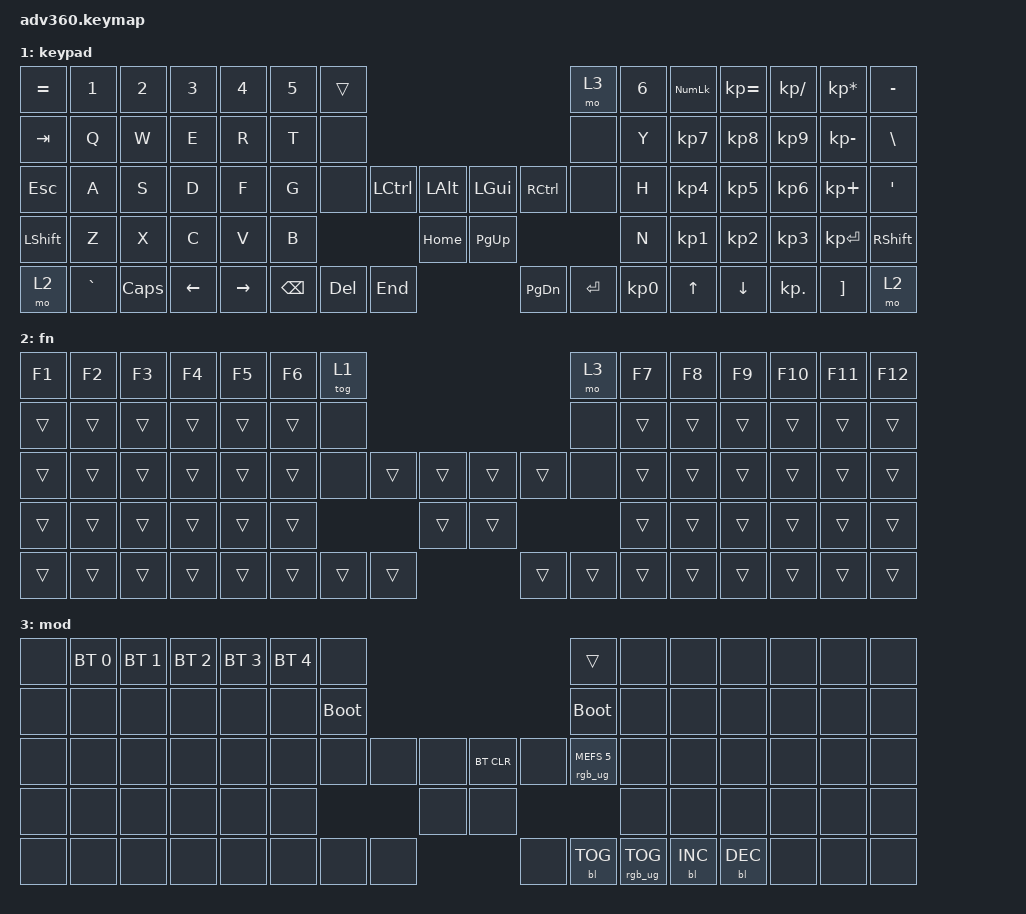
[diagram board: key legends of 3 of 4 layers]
#include <behaviors.dtsi>
#include <dt-bindings/zmk/keys.h>
#include <dt-bindings/zmk/bt.h>
#include <dt-bindings/zmk/rgb.h>
#include <dt-bindings/zmk/backlight.h>
#include "adv360_keypos.h"

#define QUICK_TAP_MS 175
#define XXX &none
#define ___ &trans

#define KEYS_L LN0 LN1 LN2 LN3 LN4 LN5 LT0 LT1 LT2 LT3 LT4 LT5 LM0 LM1 LM2 LM3 LM4 LM5 LB0 LB1 LB2 LB3 LB4 LB5  // left-hand keys
#define KEYS_R RN0 RN1 RN2 RN3 RN4 RN5 RT0 RT1 RT2 RT3 RT4 RT5 RM0 RM1 RM2 RM3 RM4 RM5 RB0 RB1 RB2 RB3 RB4 RB5  // right-hand keys
#define THUMBS LH2 LH1 LH0 RH0 RH1 RH2

#define ZMK_HELPER_STRINGIFY(x) #x
/* ZMK_BEHAVIOR */

#define ZMK_BEHAVIOR_CORE_caps_word       compatible = "zmk,behavior-caps-word";       #binding-cells = <0>
#define ZMK_BEHAVIOR_CORE_dynamic_macro   compatible = "zmk,behavior-dynamic-macro";   #binding-cells = <1>
#define ZMK_BEHAVIOR_CORE_hold_tap        compatible = "zmk,behavior-hold-tap";        #binding-cells = <2>
#define ZMK_BEHAVIOR_CORE_key_repeat      compatible = "zmk,behavior-key-repeat";      #binding-cells = <0>
#define ZMK_BEHAVIOR_CORE_macro           compatible = "zmk,behavior-macro";           #binding-cells = <0>
#define ZMK_BEHAVIOR_CORE_macro_one_param compatible = "zmk,behavior-macro-one-param"; #binding-cells = <1>
#define ZMK_BEHAVIOR_CORE_macro_two_param compatible = "zmk,behavior-macro-two-param"; #binding-cells = <2>
#define ZMK_BEHAVIOR_CORE_mod_morph       compatible = "zmk,behavior-mod-morph";       #binding-cells = <0>
#define ZMK_BEHAVIOR_CORE_sticky_key      compatible = "zmk,behavior-sticky-key";      #binding-cells = <1>
#define ZMK_BEHAVIOR_CORE_tap_dance       compatible = "zmk,behavior-tap-dance";       #binding-cells = <0>
#define ZMK_BEHAVIOR_CORE_tri_state       compatible = "zmk,behavior-tri-state";       #binding-cells = <0>

#define ZMK_BEHAVIOR(name, type, ...) \
    / { \
        behaviors { \
            name: name { \
                label = ZMK_HELPER_STRINGIFY(ZB_ ## name); \
                ZMK_BEHAVIOR_CORE_ ## type; \
                __VA_ARGS__ \
            }; \
        }; \
    };

// removed         //global-quick-tap-ms = <150>;
#define MAKE_HRM(NAME, HOLD, TAP, TRIGGER_POS) \
    ZMK_BEHAVIOR(NAME, hold_tap, \
        flavor = "tap-unless-interrupted"; \
        tapping-term-ms = <200>; \
        quick-tap-ms = <QUICK_TAP_MS>; \
        global-quick-tap; \
        bindings = <HOLD>, <TAP>; \
        hold-trigger-key-positions = <TRIGGER_POS>; \
        hold-trigger-on-release; \
    )
MAKE_HRM(hml, &kp, &kp, KEYS_R THUMBS)  // left-hand HRMs
MAKE_HRM(hmr, &kp, &kp, KEYS_L THUMBS)  // right-hand HRMs

//MAKE_HRM(hml_repeat, &kp, &key_repeat, KEYS_R THUMBS)  // used for HRM-combo
//MAKE_HRM(hmr_lpar_lt, &kp, &lpar_lt, KEYS_L THUMBS)    // "    "   "   "
//MAKE_HRM(hmr_rpar_gt, &kp, &rpar_gt, KEYS_L THUMBS)    // "    "   "   "

//#define AS(keycode) &as LS(keycode) keycode     // Autoshift Macro
#define HYP LC(LA(LGUI))
#define CW &caps_word
//#define _SCRNS &kp LG(LS(NUMBER_4))

/ {
    behaviors {
      #include "macros.dtsi"
    };

  keymap {
    compatible = "zmk,keymap";

    default_layer {
      bindings = <
        &kp EQUAL &kp N1    &kp N2   &kp N3   &kp N4     &kp N5 &tog 1                                                           &mo 3 &kp N6 &kp N7 &kp N8    &kp N9   &kp N0   &kp MINUS
        &kp TAB   &kp Q     &kp W    &kp E    &kp R      &kp T  &none                                                            &none &kp Y  &kp U  &kp I     &kp O    &kp P    &kp BSLH
        &mt HYP ESC   &hml LCTRL A     &hml LALT S    &hml LSHFT D    &hml LGUI F      &kp G  &none           &kp LCTRL &kp LALT &kp LGUI  &kp RCTRL           &none &kp H  &hmr LGUI J  &hmr RSHFT K     &hmr RALT L    &hmr RCTL SEMI &mt HYP SQT
        &kp LSHFT &kp Z     &kp X    &kp C    &kp V      &kp B                            &kp HOME &kp PG_UP                           &kp N  &kp M  &kp COMMA &kp DOT  &kp FSLH &kp RSHFT
        &mo 2     &kp GRAVE &kp CW &kp LEFT &kp RIGHT                &kp BSPC &kp DEL   &kp END  &kp PG_DN &kp ENTER &kp SPACE              &kp UP &kp DOWN  &kp LBKT &kp RBKT &mo 2
      >;
    };
    keypad {
      bindings = <
        &kp EQUAL &kp N1    &kp N2   &kp N3   &kp N4     &kp N5 &trans                                                           &mo 3 &kp N6 &kp KP_NUM &kp KP_EQUAL &kp KP_DIVIDE &kp KP_MULTIPLY &kp MINUS
        &kp TAB   &kp Q     &kp W    &kp E    &kp R      &kp T  &none                                                            &none &kp Y  &kp KP_N7  &kp KP_N8    &kp KP_N9     &kp KP_MINUS    &kp BSLH
        &kp ESC   &kp A     &kp S    &kp D    &kp F      &kp G  &none           &kp LCTRL &kp LALT &kp LGUI  &kp RCTRL           &none &kp H  &kp KP_N4  &kp KP_N5    &kp KP_N6     &kp KP_PLUS     &kp SQT
        &kp LSHFT &kp Z     &kp X    &kp C    &kp V      &kp B                            &kp HOME &kp PG_UP                           &kp N  &kp KP_N1  &kp KP_N2    &kp KP_N3     &kp KP_ENTER    &kp RSHFT
        &mo 2     &kp GRAVE &kp CAPS &kp LEFT &kp RIGHT                &kp BSPC &kp DEL   &kp END  &kp PG_DN &kp ENTER &kp KP_N0              &kp UP     &kp DOWN     &kp KP_DOT    &kp RBKT        &mo 2
      >;
    };
    fn {
      bindings = <
        &kp F1 &kp F2 &kp F3 &kp F4 &kp F5 &kp F6 &tog 1                                           &mo 3 &kp F7 &kp F8 &kp F9 &kp F10 &kp F11 &kp F12
        &trans &trans &trans &trans &trans &trans  &none                                           &none &trans &trans &trans &trans  &trans  &trans
        &trans &trans &trans &trans &trans &trans  &none        &trans &trans &trans &trans        &none &trans &trans &trans &trans  &trans  &trans
        &trans &trans &trans &trans &trans &trans                      &trans &trans                     &trans &trans &trans &trans  &trans  &trans
        &trans &trans &trans &trans &trans               &trans &trans &trans &trans &trans &trans              &trans &trans &trans  &trans  &trans
      >;
    };
    mod {
      bindings = <
        &none &bt BT_SEL 0 &bt BT_SEL 1 &bt BT_SEL 2 &bt BT_SEL 3 &bt BT_SEL 4 &none                                                                     &trans                 &none        &none        &none        &none &none &none
        &none &none        &none        &none        &none        &none        &bootloader                                                               &bootloader            &none        &none        &none        &none &none &none
        &none &none        &none        &none        &none        &none        &none                   &none &none &bt BT_CLR &none                      &rgb_ug RGB_MEFS_CMD 5 &none        &none        &none        &none &none &none
        &none &none        &none        &none        &none        &none                                      &none &none                                                        &none        &none        &none        &none &none &none
        &none &none        &none        &none        &none                                       &none &none &none &none      &bl BL_TOG &rgb_ug RGB_TOG                                     &bl BL_INC   &bl BL_DEC   &none &none &none
      >;
    };
  };
};
